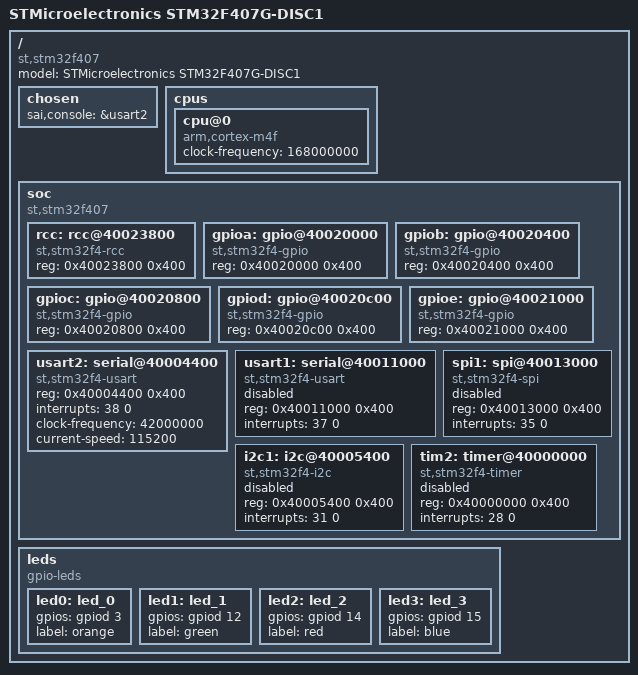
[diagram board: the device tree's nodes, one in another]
/dts-v1/;

/ {
    model = "STMicroelectronics STM32F407G-DISC1";
    compatible = "st,stm32f407";

    #address-cells = <1>;
    #size-cells = <1>;

    chosen {
        sai,console = &usart2;
    };

    cpus {
        #address-cells = <1>;
        #size-cells = <0>;
        cpu@0 {
            device_type = "cpu";
            compatible = "arm,cortex-m4f";
            clock-frequency = <168000000>;
        };
    };

    soc {
        #address-cells = <1>;
        #size-cells = <1>;
        compatible = "st,stm32f407", "simple-bus";
        ranges;

        rcc: rcc@40023800 {
            compatible = "st,stm32f4-rcc";
            reg = <0x40023800 0x400>;
        };

        gpioa: gpio@40020000 { compatible = "st,stm32f4-gpio"; reg = <0x40020000 0x400>; };
        gpiob: gpio@40020400 { compatible = "st,stm32f4-gpio"; reg = <0x40020400 0x400>; };
        gpioc: gpio@40020800 { compatible = "st,stm32f4-gpio"; reg = <0x40020800 0x400>; };
        gpiod: gpio@40020c00 { compatible = "st,stm32f4-gpio"; reg = <0x40020c00 0x400>; };
        gpioe: gpio@40021000 { compatible = "st,stm32f4-gpio"; reg = <0x40021000 0x400>; };

        usart2: serial@40004400 {
            compatible = "st,stm32f4-usart";
            reg = <0x40004400 0x400>;
            interrupts = <38 0>;
            clock-frequency = <42000000>;
            current-speed = <115200>;
            status = "okay";
        };

        usart1: serial@40011000 {
            compatible = "st,stm32f4-usart";
            reg = <0x40011000 0x400>;
            interrupts = <37 0>;
            status = "disabled";
        };

        spi1: spi@40013000 {
            compatible = "st,stm32f4-spi";
            reg = <0x40013000 0x400>;
            interrupts = <35 0>;
            status = "disabled";
        };

        i2c1: i2c@40005400 {
            compatible = "st,stm32f4-i2c";
            reg = <0x40005400 0x400>;
            interrupts = <31 0>;
            status = "disabled";
        };

        tim2: timer@40000000 {
            compatible = "st,stm32f4-timer";
            reg = <0x40000000 0x400>;
            interrupts = <28 0>;
            status = "disabled";
        };
    };

    leds {
        compatible = "gpio-leds";
        led0: led_0 {
            gpios = <&gpiod 3 0>;    /* LD3 orange */
            label = "orange";
        };
        led1: led_1 {
            gpios = <&gpiod 12 0>;   /* LD4 green  */
            label = "green";
        };
        led2: led_2 {
            gpios = <&gpiod 14 0>;   /* LD5 red    */
            label = "red";
        };
        led3: led_3 {
            gpios = <&gpiod 15 0>;   /* LD6 blue   */
            label = "blue";
        };
    };
};
